VERSION ""

NS_ :

BS_:

BU_: HIL Clutch_Act

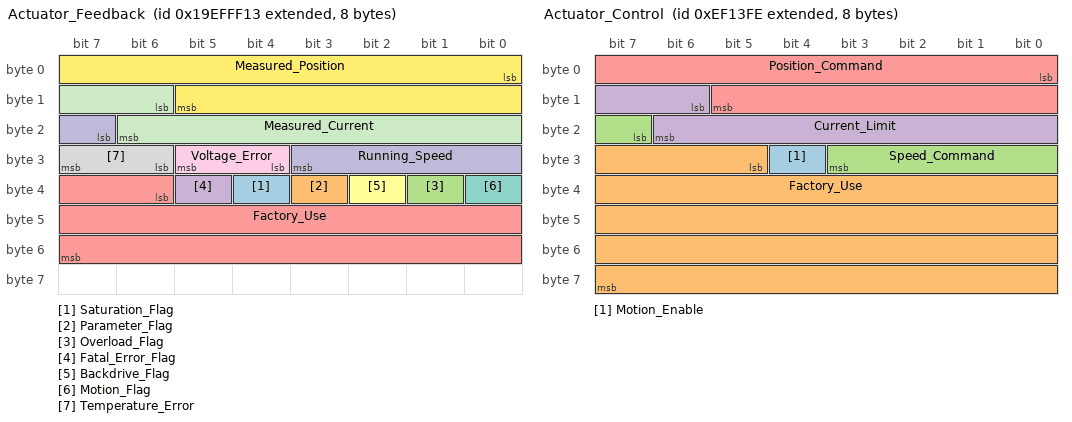
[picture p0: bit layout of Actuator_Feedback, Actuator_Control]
BO_ 2582642451 Actuator_Feedback: 8 Clutch_Act
 SG_ Saturation_Flag : 36|1@1- (1,0) [0|0] ""  HIL
 SG_ Parameter_Flag : 35|1@1- (1,0) [0|0] ""  HIL
 SG_ Overload_Flag : 33|1@1- (1,0) [0|0] ""  HIL
 SG_ Fatal_Error_Flag : 37|1@1- (1,0) [0|0] ""  HIL
 SG_ Factory_Use : 38|18@1- (1,0) [0|0] ""  HIL
 SG_ Backdrive_Flag : 34|1@1- (1,0) [0|0] ""  HIL
 SG_ Motion_Flag : 32|1@1- (1,0) [0|0] ""  HIL
 SG_ Temperature_Error : 30|2@1- (1,0) [0|0] ""  HIL
 SG_ Voltage_Error : 28|2@1- (1,0) [0|0] ""  HIL
 SG_ Running_Speed : 23|5@1- (5,0) [0|0] ""  HIL
 SG_ Measured_Current : 14|9@1- (0.1,0) [0|0] ""  HIL
 SG_ Measured_Position : 0|14@1- (0.1,0) [0|0] ""  HIL

BO_ 2163151870 Actuator_Control: 8 HIL
 SG_ Motion_Enable : 28|1@1- (1,0) [0|0] ""  Clutch_Act
 SG_ Factory_Use : 29|35@1- (1,0) [0|0] ""  Clutch_Act
 SG_ Speed_Command : 23|5@1- (1,0) [0|0] ""  Clutch_Act
 SG_ Current_Limit : 14|9@1- (0.1,0) [0|0] ""  Clutch_Act
 SG_ Position_Command : 0|14@1- (0.1,0) [0|0] ""  Clutch_Act

CM_ SG_ 2582642451 Running_Speed "[% DC]";
CM_ SG_ 2582642451 Measured_Current "[A]";
CM_ SG_ 2582642451 Measured_Position "[mm]";
CM_ SG_ 2163151870 Current_Limit "[A]";
CM_ SG_ 2163151870 Position_Command "[mm]
";
